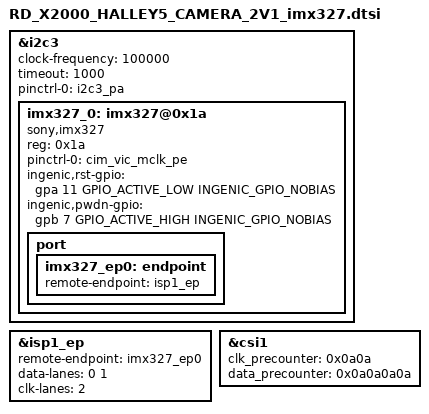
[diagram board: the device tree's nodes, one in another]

&i2c3 {
	status = "okay";
	clock-frequency = <100000>;
	timeout = <1000>;
	pinctrl-names = "default";
	pinctrl-0 = <&i2c3_pa>;


	/*RD_X2000_HALLEY5_CAMERA_imx335 MIPI interface*/
	imx327_0:imx327@0x1a {
		status = "ok";
		compatible = "sony,imx327";
		reg = <0x1a>;
		pinctrl-names = "default";
		pinctrl-0 = <&cim_vic_mclk_pe>;

		ingenic,rst-gpio = <&gpa 11 GPIO_ACTIVE_LOW INGENIC_GPIO_NOBIAS>;
		ingenic,pwdn-gpio = <&gpb 7 GPIO_ACTIVE_HIGH INGENIC_GPIO_NOBIAS>;

		port {
			imx327_ep0:endpoint {
				remote-endpoint = <&isp1_ep>;
			};
		};
	};
};

&isp1_ep {
	remote-endpoint = <&imx327_ep0>;
	data-lanes = <0 1>;
	clk-lanes = <2>;
};


&csi1 {
	clk_precounter = <0x0a0a>;   /* (precounter_in_clk1 << 8) | precounter_in_clk0*/
	data_precounter = <0x0a0a0a0a>; /* (precounter_in_data3 << 24)|(precounter_in_data2 << 16)|(precounter_in_data1 << 8)|precounter_in_data0 */
};
